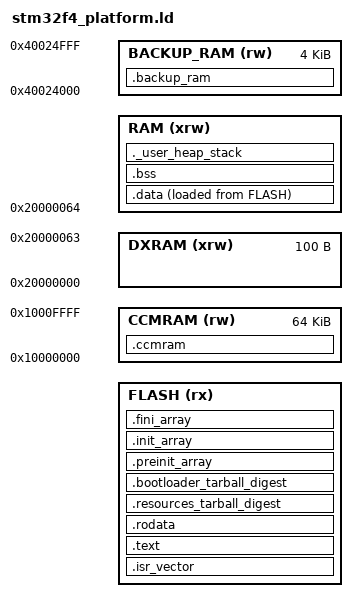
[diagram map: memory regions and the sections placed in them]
/*
******************************************************************************
File:     stm32f4_platform.ld
Info:     Based on a linker script generated by Atollic TrueSTUDIO(R) 9.3.0

Abstract: Shared linker script for the STM32F4 main-board firmware
          (STM32F407VG and STM32F42x).

The MIT License (MIT)
Copyright (c) 2019 STMicroelectronics

Permission is hereby granted, free of charge, to any person obtaining a copy
of this software and associated documentation files (the "Software"), to deal
in the Software without restriction, including without limitation the rights
to use, copy, modify, merge, publish, distribute, sublicense, and/or sell
copies of the Software, and to permit persons to whom the Software is
furnished to do so, subject to the following conditions:

The above copyright notice and this permission notice shall be included in all
copies or substantial portions of the Software.

THE SOFTWARE IS PROVIDED "AS IS", WITHOUT WARRANTY OF ANY KIND, EXPRESS OR
IMPLIED, INCLUDING BUT NOT LIMITED TO THE WARRANTIES OF MERCHANTABILITY,
FITNESS FOR A PARTICULAR PURPOSE AND NONINFRINGEMENT. IN NO EVENT SHALL THE
AUTHORS OR COPYRIGHT HOLDERS BE LIABLE FOR ANY CLAIM, DAMAGES OR OTHER
LIABILITY, WHETHER IN AN ACTION OF CONTRACT, TORT OR OTHERWISE, ARISING FROM,
OUT OF OR IN CONNECTION WITH THE SOFTWARE OR THE USE OR OTHER DEALINGS IN THE
SOFTWARE.

******************************************************************************
*/

/* Entry Point */
ENTRY(Reset_Handler)

/* RAM is split into Data-eXchange-RAM and regular RAM. RAM_SIZE_TOTAL comes
   from the including wrapper. */
DXRAM_BASE = 0x20000000;
DXRAM_SIZE = 100;
RAM_BASE = DXRAM_BASE + DXRAM_SIZE;
RAM_SIZE = RAM_SIZE_TOTAL - DXRAM_SIZE;

/* Highest address of the user mode stack (end of main RAM) */
_estack = DXRAM_BASE + RAM_SIZE_TOTAL;

/* Generate a link error if heap and stack don't fit into RAM */
_Min_Heap_Size = 0x800;      /* required amount of heap  */
_Min_Stack_Size = 0x800; /* required amount of stack */

/* Specify the memory areas. FLASH_ORIGIN / FLASH_LENGTH come from the including
   wrapper. */
MEMORY
{
  FLASH (rx)      : ORIGIN = FLASH_ORIGIN, LENGTH = FLASH_LENGTH
  DXRAM (xrw)     : ORIGIN = DXRAM_BASE, LENGTH = DXRAM_SIZE
  RAM (xrw)       : ORIGIN = RAM_BASE,   LENGTH = RAM_SIZE
  CCMRAM (rw)     : ORIGIN = 0x10000000, LENGTH = 64K
  BACKUP_RAM (rw) : ORIGIN = 0x40024000, LENGTH = 4K
}

EXTERN (_scanf_float) /* Require proper _scanf_float rather than a stub */

/* Define output sections */
SECTIONS
{
  /* Disable usage of some functions */
  /DISCARD/ :
  {
    /* These functions dynamically allocate. Use their _r variant. */
    *(.text.asctime)
    *(.text.gmtime)
    *(.text.localtime)
    *(.text.ctime)
  }

  /* The startup code goes first into FLASH */
  .isr_vector :
  {
    . = ALIGN(4);
    KEEP(*(.isr_vector)) /* Startup code */
    . = ALIGN(4);
  } >FLASH

  .backup_ram (NOLOAD):
  {
    . = ALIGN(4);
    *(.backup_ram)
  } >BACKUP_RAM

  /* The program code and other data goes into FLASH */
  .text :
  {
    . = ALIGN(4);
    *(.text)           /* .text sections (code) */
    *(.text*)          /* .text* sections (code) */
    *(.glue_7)         /* glue arm to thumb code */
    *(.glue_7t)        /* glue thumb to arm code */
    *(.eh_frame)

    KEEP (*(.init))
    KEEP (*(.fini))

    . = ALIGN(4);
    _etext = .;        /* define a global symbols at end of code */
  } >FLASH

  /* Constant data goes into FLASH */
  .rodata :
  {
    . = ALIGN(4);
    *(.rodata)         /* .rodata sections (constants, strings, etc.) */
    *(.rodata*)        /* .rodata* sections (constants, strings, etc.) */
    . = ALIGN(4);
  } >FLASH

  .resources_tarball_digest : {
    KEEP(*(.resources_tarball_digest))
  } >FLASH
  .bootloader_tarball_digest : {
    KEEP(*(.bootloader_tarball_digest))
  } >FLASH

  .preinit_array     :
  {
    PROVIDE_HIDDEN (__preinit_array_start = .);
    KEEP (*(.preinit_array*))
    PROVIDE_HIDDEN (__preinit_array_end = .);
  } >FLASH
  .init_array :
  {
    PROVIDE_HIDDEN (__init_array_start = .);
    KEEP (*(SORT(.init_array.*)))
    KEEP (*(.init_array*))
    PROVIDE_HIDDEN (__init_array_end = .);
  } >FLASH
  .fini_array :
  {
    PROVIDE_HIDDEN (__fini_array_start = .);
    KEEP (*(SORT(.fini_array.*)))
    KEEP (*(.fini_array*))
    PROVIDE_HIDDEN (__fini_array_end = .);
  } >FLASH

  /* used by the startup to initialize data */
  _sidata = LOADADDR(.data);

  /* Initialized data sections goes into RAM, load LMA copy after code */
  .data :
  {
    . = ALIGN(4);
    _sdata = .;        /* create a global symbol at data start */

    PROVIDE_HIDDEN (__start_log_components = .);
    KEEP(*(.data.log_components))
    PROVIDE_HIDDEN (__end_log_components = .);

    PROVIDE_HIDDEN (__start_metric_definitions = .);
    KEEP(*(SORT(.data.metric_definitions.*)))
    PROVIDE_HIDDEN (__end_metric_definitions = .);

    *(.data)           /* .data sections */
    *(.data*)          /* .data* sections */
    *(.RamFunc)        /* .RamFunc sections */
    *(.RamFunc*)       /* .RamFunc* sections */

    . = ALIGN(4);
    _edata = .;        /* define a global symbol at data end */
  } >RAM AT> FLASH

  _siccmram = LOADADDR(.ccmram);

  /* CCM-RAM section
  *
  * IMPORTANT NOTE!
  * If initialized variables will be placed in this section,
  * the startup code needs to be modified to copy the init-values.
  */
  .ccmram (NOLOAD) :
  {
    . = ALIGN(4);
    _sccmram = .;       /* create a global symbol at ccmram start */
    *(.ccmram_beginning)
    *(.ccmram)
    *(.ccmram*)

    . = ALIGN(4);
    _eccmram = .;       /* create a global symbol at ccmram end */
  } >CCMRAM

  /* Uninitialized data section */
  . = ALIGN(4);
  .bss :
  {
    /* This is used by the startup in order to initialize the .bss secion */
    _sbss = .;         /* define a global symbol at bss start */
    __bss_start__ = _sbss;
    *(.bss)
    *(.bss*)
    *(COMMON)

    . = ALIGN(4);
    _ebss = .;         /* define a global symbol at bss end */
    __bss_end__ = _ebss;
  } >RAM

  /* User_heap_stack section, used to check that there is enough RAM left */
  ._user_heap_stack :
  {
    . = ALIGN(4);
    PROVIDE ( end = . );
    PROVIDE ( _end = . );
    . = . + _Min_Heap_Size;
    . = . + _Min_Stack_Size;
    . = ALIGN(4);
  } >RAM

  /* Remove information from the standard libraries */
  /DISCARD/ :
  {
    libc.a:* ( * )
    libm.a:* ( * )
    libgcc.a:* ( * )
    *(.ARM.exidx*)
    *(.ARM.extab* .gnu.linkonce.armextab.*)
  }

  .ARM.attributes 0 : { *(.ARM.attributes) }
}
